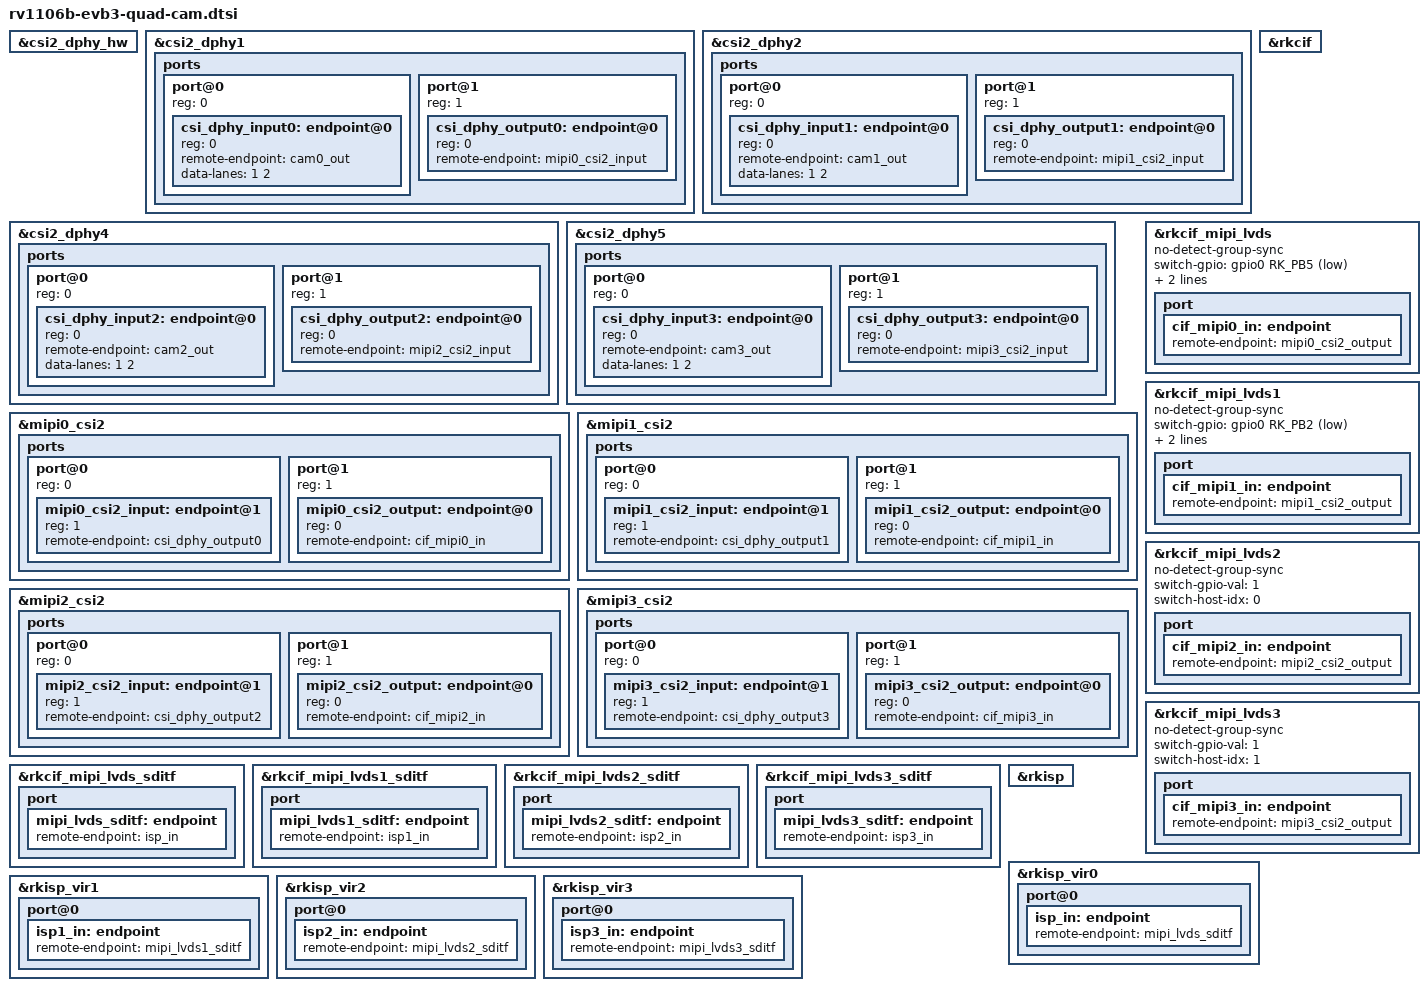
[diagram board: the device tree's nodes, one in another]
// SPDX-License-Identifier: (GPL-2.0+ OR MIT)
/*
 * Copyright (c) 2026 Rockchip Electronics Co., Ltd.
 *
 */

/*
 * i2c4_0x30->dphy1->rkcif_mipi_lvds
 * i2c1_0x30->dphy2->rkcif_mipi_lvds1
 * i2c4_0x32->dphy4->rkcif_mipi_lvds2
 * i2c1_0x32->dphy5->rkcif_mipi_lvds3
 */

&csi2_dphy_hw {
	status = "okay";
};

&csi2_dphy1 {
	status = "okay";

	ports {
		#address-cells = <1>;
		#size-cells = <0>;

		port@0 {
			reg = <0>;
			#address-cells = <1>;
			#size-cells = <0>;

			csi_dphy_input0: endpoint@0 {
				reg = <0>;
				remote-endpoint = <&cam0_out>;
				data-lanes = <1 2>;
			};
		};

		port@1 {
			reg = <1>;
			#address-cells = <1>;
			#size-cells = <0>;

			csi_dphy_output0: endpoint@0 {
				reg = <0>;
				remote-endpoint = <&mipi0_csi2_input>;
			};
		};
	};
};

&csi2_dphy2 {
	status = "okay";

	ports {
		#address-cells = <1>;
		#size-cells = <0>;

		port@0 {
			reg = <0>;
			#address-cells = <1>;
			#size-cells = <0>;

			csi_dphy_input1: endpoint@0 {
				reg = <0>;
				remote-endpoint = <&cam1_out>;
				data-lanes = <1 2>;
			};
		};

		port@1 {
			reg = <1>;
			#address-cells = <1>;
			#size-cells = <0>;

			csi_dphy_output1: endpoint@0 {
				reg = <0>;
				remote-endpoint = <&mipi1_csi2_input>;
			};
		};
	};
};

&csi2_dphy4 {
	status = "okay";

	ports {
		#address-cells = <1>;
		#size-cells = <0>;

		port@0 {
			reg = <0>;
			#address-cells = <1>;
			#size-cells = <0>;

			csi_dphy_input2: endpoint@0 {
				reg = <0>;
				remote-endpoint = <&cam2_out>;
				data-lanes = <1 2>;
			};
		};

		port@1 {
			reg = <1>;
			#address-cells = <1>;
			#size-cells = <0>;

			csi_dphy_output2: endpoint@0 {
				reg = <0>;
				remote-endpoint = <&mipi2_csi2_input>;
			};
		};
	};
};

&csi2_dphy5 {
	status = "okay";

	ports {
		#address-cells = <1>;
		#size-cells = <0>;

		port@0 {
			reg = <0>;
			#address-cells = <1>;
			#size-cells = <0>;

			csi_dphy_input3: endpoint@0 {
				reg = <0>;
				remote-endpoint = <&cam3_out>;
				data-lanes = <1 2>;
			};
		};

		port@1 {
			reg = <1>;
			#address-cells = <1>;
			#size-cells = <0>;

			csi_dphy_output3: endpoint@0 {
				reg = <0>;
				remote-endpoint = <&mipi3_csi2_input>;
			};
		};
	};
};


&mipi0_csi2 {
	status = "okay";

	ports {
		#address-cells = <1>;
		#size-cells = <0>;

		port@0 {
			reg = <0>;
			#address-cells = <1>;
			#size-cells = <0>;

			mipi0_csi2_input: endpoint@1 {
				reg = <1>;
				remote-endpoint = <&csi_dphy_output0>;
			};
		};

		port@1 {
			reg = <1>;
			#address-cells = <1>;
			#size-cells = <0>;

			mipi0_csi2_output: endpoint@0 {
				reg = <0>;
				remote-endpoint = <&cif_mipi0_in>;
			};
		};
	};
};

&mipi1_csi2 {
	status = "okay";

	ports {
		#address-cells = <1>;
		#size-cells = <0>;

		port@0 {
			reg = <0>;
			#address-cells = <1>;
			#size-cells = <0>;

			mipi1_csi2_input: endpoint@1 {
				reg = <1>;
				remote-endpoint = <&csi_dphy_output1>;
			};
		};

		port@1 {
			reg = <1>;
			#address-cells = <1>;
			#size-cells = <0>;

			mipi1_csi2_output: endpoint@0 {
				reg = <0>;
				remote-endpoint = <&cif_mipi1_in>;
			};
		};
	};
};

&mipi2_csi2 {
	status = "okay";

	ports {
		#address-cells = <1>;
		#size-cells = <0>;

		port@0 {
			reg = <0>;
			#address-cells = <1>;
			#size-cells = <0>;

			mipi2_csi2_input: endpoint@1 {
				reg = <1>;
				remote-endpoint = <&csi_dphy_output2>;
			};
		};

		port@1 {
			reg = <1>;
			#address-cells = <1>;
			#size-cells = <0>;

			mipi2_csi2_output: endpoint@0 {
				reg = <0>;
				remote-endpoint = <&cif_mipi2_in>;
			};
		};
	};
};

&mipi3_csi2 {
	status = "okay";

	ports {
		#address-cells = <1>;
		#size-cells = <0>;

		port@0 {
			reg = <0>;
			#address-cells = <1>;
			#size-cells = <0>;

			mipi3_csi2_input: endpoint@1 {
				reg = <1>;
				remote-endpoint = <&csi_dphy_output3>;
			};
		};

		port@1 {
			reg = <1>;
			#address-cells = <1>;
			#size-cells = <0>;

			mipi3_csi2_output: endpoint@0 {
				reg = <0>;
				remote-endpoint = <&cif_mipi3_in>;
			};
		};
	};
};

&rkcif {
	status = "okay";
};

&rkcif_mipi_lvds {
	status = "okay";
	no-detect-group-sync;
	switch-gpio = <&gpio0 RK_PB5 GPIO_ACTIVE_LOW>;
	switch-gpio-val = <0>;
	switch-host-idx = <0>;

	port {
		/* MIPI CSI-2 endpoint */
		cif_mipi0_in: endpoint {
			remote-endpoint = <&mipi0_csi2_output>;
		};
	};
};

&rkcif_mipi_lvds1 {
	status = "okay";
	no-detect-group-sync;
	switch-gpio = <&gpio0 RK_PB2 GPIO_ACTIVE_LOW>;
	switch-gpio-val = <0>;
	switch-host-idx = <1>;

	port {
		/* MIPI CSI-2 endpoint */
		cif_mipi1_in: endpoint {
			remote-endpoint = <&mipi1_csi2_output>;
		};
	};
};


&rkcif_mipi_lvds2 {
	status = "okay";
	no-detect-group-sync;
	switch-gpio-val = <1>;
	switch-host-idx = <0>;

	port {
		/* MIPI CSI-2 endpoint */
		cif_mipi2_in: endpoint {
			remote-endpoint = <&mipi2_csi2_output>;
		};
	};
};

&rkcif_mipi_lvds3 {
	status = "okay";
	no-detect-group-sync;
	switch-gpio-val = <1>;
	switch-host-idx = <1>;

	port {
		/* MIPI CSI-2 endpoint */
		cif_mipi3_in: endpoint {
			remote-endpoint = <&mipi3_csi2_output>;
		};
	};
};

&rkcif_mipi_lvds_sditf {
	status = "okay";

	port {
		/* MIPI CSI-2 endpoint */
		mipi_lvds_sditf: endpoint {
			remote-endpoint = <&isp_in>;
		};
	};
};

&rkcif_mipi_lvds1_sditf {
	status = "okay";

	port {
		/* MIPI CSI-2 endpoint */
		mipi_lvds1_sditf: endpoint {
			remote-endpoint = <&isp1_in>;
		};
	};
};

&rkcif_mipi_lvds2_sditf {
	status = "okay";

	port {
		/* MIPI CSI-2 endpoint */
		mipi_lvds2_sditf: endpoint {
			remote-endpoint = <&isp2_in>;
		};
	};
};

&rkcif_mipi_lvds3_sditf {
	status = "okay";

	port {
		/* MIPI CSI-2 endpoint */
		mipi_lvds3_sditf: endpoint {
			remote-endpoint = <&isp3_in>;
		};
	};
};

&rkisp {
	status = "okay";
};

&rkisp_vir0 {
	status = "okay";

	port@0 {
		isp_in: endpoint {
			remote-endpoint = <&mipi_lvds_sditf>;
		};
	};
};

&rkisp_vir1 {
	status = "okay";

	port@0 {
		isp1_in: endpoint {
			remote-endpoint = <&mipi_lvds1_sditf>;
		};
	};
};

&rkisp_vir2 {
	status = "okay";

	port@0 {
		isp2_in: endpoint {
			remote-endpoint = <&mipi_lvds2_sditf>;
		};
	};
};

&rkisp_vir3 {
	status = "okay";

	port@0 {
		isp3_in: endpoint {
			remote-endpoint = <&mipi_lvds3_sditf>;
		};
	};
};
